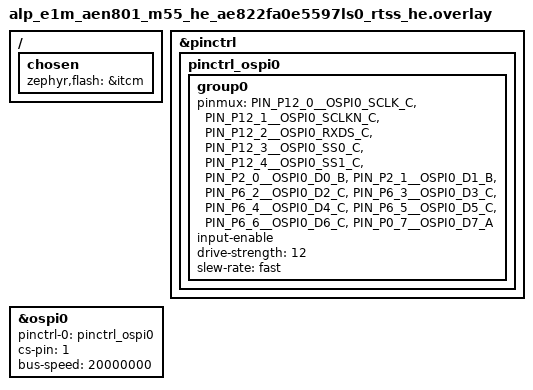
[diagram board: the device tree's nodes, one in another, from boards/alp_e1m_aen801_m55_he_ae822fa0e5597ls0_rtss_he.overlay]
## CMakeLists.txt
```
# SPDX-License-Identifier: Apache-2.0
#
# aen-ospi-regcheck -- compile + DT-bind proof of the Alif Ensemble OSPI/HexSPI
# controller (Synopsys DesignWare OSPI, zephyr/drivers/flash/flash_ospi_alif.c,
# compatible "snps,designware-ospi") staging on the E1M-AEN801 and E1M-AEN803
# (both Ensemble E8, M55-HE), via the bench RAM-run + RAM-console flow.
#
# Plain prj.conf app (no alp_project.py board.yaml emit). BUILD-ONLY: this
# proves the ospi0 node BINDS + alif_hal_ospi_initialize() compiles, links,
# and the register file reads back live -- not a live XiP read (XiP setup is
# a deliberate SKIP: OSPI_XIP_SER does not exist on AE822, independent of
# what's populated on the bus -- see src/main.c's CORRECTED PREMISE note,
# #2041) and not a device-level transfer of any kind (controller-register
# proof only). See src/main.c + the board overlay.

cmake_minimum_required(VERSION 3.20)

# No DTC_OVERLAY_FILE: Zephyr applies boards/<fully-qualified-board>.overlay by
# itself -- alp_e1m_aen801_m55_he_ae822fa0e5597ls0_rtss_he.overlay for
# `-b alp_e1m_aen801_m55_he/ae822fa0e5597ls0/rtss_he`, the aen803 file for the
# AEN803 target -- ITCM retarget included. Pinning the AEN801 file here, as
# this file used to, handed the AEN801 overlay to an AEN803 build and left the
# AEN803 one unread.

find_package(Zephyr REQUIRED HINTS $ENV{ZEPHYR_BASE})
project(aen_ospi_regcheck LANGUAGES C)

target_sources(app PRIVATE src/main.c)
```

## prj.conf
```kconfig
# SPDX-License-Identifier: Apache-2.0
#
# Bench RAM-run config for the E1M-AEN801 and E1M-AEN803 (M55-HE).

# Tier-1.5 driver Kconfigs (incl. CONFIG_OSPI_ALIF) are gated under ALP_SDK.
CONFIG_ALP_SDK=y

# This regcheck is specifically for the Ensemble E8 (E1M-AEN801 / E1M-AEN803).
CONFIG_ALP_SOC_ALIF_ENSEMBLE_E8=y

# The OSPI/HexSPI Tier-1.5 driver (zephyr/drivers/flash/flash_ospi_alif.c) --
# BUILD-ONLY: this app makes no device-level OSPI transfer (see src/main.c),
# only controller-register reads.  Pulls in USE_ALIF_HAL_OSPI (modules/hal/
# alif drivers/ospi).
CONFIG_OSPI_ALIF=y
CONFIG_FLASH=y

# CRC32 for the #915 program/erase self-test (src/main.c,
# AEN_OSPI_ENABLE_PROGRAM_ERASE_SELFTEST) -- off by default, but always
# compiled, so this Kconfig is always needed regardless of that flag.
CONFIG_CRC=y

# Console: Alp UART console -- E1M edge UART0 (Alif UART5, P3_4/P3_5, 115200
# 8N1, NS16550), the E1M-AEN carrier console. The board _defconfig already
# selects it; we set it explicitly here so the example is self-describing.
CONFIG_SERIAL=y
CONFIG_CONSOLE=y
CONFIG_UART_CONSOLE=y
CONFIG_UART_INTERRUPT_DRIVEN=y
# Serial-less bench? Comment the four lines above and uncomment these to read
# 'ram_console_buf' over SWD instead:
# CONFIG_RAM_CONSOLE=y
# CONFIG_RAM_CONSOLE_BUFFER_SIZE=2048
# CONFIG_UART_CONSOLE=n
CONFIG_PRINTK=y

# Keep the image small + deterministic for a RAM-run.
CONFIG_LOG=n
```

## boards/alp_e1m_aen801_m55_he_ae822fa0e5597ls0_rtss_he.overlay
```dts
/*
 * Copyright (c) 2026 Alp Lab AB
 * SPDX-License-Identifier: Apache-2.0
 *
 * aen-ospi-regcheck overlay for the E1M-AEN801 (Ensemble E8, M55-HE) RAM-run.
 *
 * Enables the Alif OSPI/HexSPI node so it BINDS on silicon:
 *   - ospi0 (snps,designware-ospi @ 0x83000000, IRQ 96, aes-reg 0x83001000,
 *     xip-base 0xA0000000/0x10000000)
 *
 * SCOPE: this proves the ospi0 node BINDS (DT_HAS_SNPS_DESIGNWARE_OSPI_ENABLED
 * + the reg/irq match) and that the flash_ospi_alif.c driver's
 * alif_hal_ospi_initialize() call compiles and links.  XiP setup itself is
 * skipped outright (OSPI_XIP_SER does not exist on AE822, independent of
 * what's on the bus -- see flash_ospi_alif.c and src/main.c).  This app
 * performs no device-level transfer, so nothing here confirms or denies a
 * part on either chip select; see src/main.c's header for the CORRECTED
 * PREMISE note (#2041) on what IS now known about SS1.
 *
 * CORRECTED (#2041): this overlay's pinctrl-0 previously muxed the Alif
 * DevKit's own OSPI0 route (zephyr_alif fork's ensemble-e4-e6-e8-pinctrl.dtsi
 * pinctrl_ospi0 "_B" group -- SCLK/RXDS/SS0 on port 3, D0-D7 on port 2), a
 * pad set that does not exist on the E1M-AEN module at all.  Because
 * flash_ospi_alif.c had no pinctrl support (see that file), pinctrl-0 was
 * also never applied, so this drove nothing regardless.  Both are fixed now:
 * the driver applies pinctrl-0 in its init, and the group below is
 * transcribed from metadata/e1m_modules/aen/alif-ospi.tsv, the E1M-AEN
 * module's actual OSPI0 routing (13 pads on ports 0/2/6/12, all function 1)
 * -- the same routing a silicon JEDEC-ID read used to confirm a populated
 * NOR at SS1 on E1M-AEN803 (see src/main.c).  Pad config
 * (input-enable/drive-strength=12/slew-rate=fast) is unchanged from the
 * prior group -- generic Alif pad electrical settings, not route-specific.
 *
 * cs-pin/bus-speed below match the paired AEN803 overlay (SS1/CS1, 20 MHz)
 * to preserve the same-PCB content invariant, even though this SKU fits no
 * OSPI memory and never transfers.
 */
#include <zephyr/dt-bindings/pinctrl/alif-ensemble-pinctrl.h>

/*
 * MANDATORY bench RAM-run retarget: run from ITCM so J-Link can loadbin+run
 * without programming MRAM, and drop the MCUboot code-partition fixup.
 */
/ {
	chosen {
		zephyr,flash = &itcm;
		/delete-property/ zephyr,code-partition;
	};
};

&pinctrl {
	pinctrl_ospi0: pinctrl_ospi0 {
		group0 {
			/* metadata/e1m_modules/aen/alif-ospi.tsv -- E1M-AEN module OSPI0
			 * routing, 13 pads, all function 1. */
			pinmux = <PIN_P12_0__OSPI0_SCLK_C>,
				 <PIN_P12_1__OSPI0_SCLKN_C>,
				 <PIN_P12_2__OSPI0_RXDS_C>,
				 <PIN_P12_3__OSPI0_SS0_C>,
				 <PIN_P12_4__OSPI0_SS1_C>,
				 <PIN_P2_0__OSPI0_D0_B>,
				 <PIN_P2_1__OSPI0_D1_B>,
				 <PIN_P6_2__OSPI0_D2_C>,
				 <PIN_P6_3__OSPI0_D3_C>,
				 <PIN_P6_4__OSPI0_D4_C>,
				 <PIN_P6_5__OSPI0_D5_C>,
				 <PIN_P6_6__OSPI0_D6_C>,
				 <PIN_P0_7__OSPI0_D7_A>;
			input-enable;
			drive-strength = <12>;
			slew-rate = "fast";
		};
	};
};

&ospi0 {
	status = "okay";
	pinctrl-0 = <&pinctrl_ospi0>;
	pinctrl-names = "default";
	cs-pin = <1>;
	bus-speed = <20000000>;
};
```

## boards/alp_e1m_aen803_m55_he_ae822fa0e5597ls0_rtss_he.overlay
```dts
/*
 * Copyright (c) 2026 Alp Lab AB
 * SPDX-License-Identifier: Apache-2.0
 *
 * aen-ospi-regcheck overlay for the E1M-AEN803 (Ensemble E8, M55-HE) RAM-run.
 *
 * Enables the Alif OSPI/HexSPI node so it BINDS on silicon:
 *   - ospi0 (snps,designware-ospi @ 0x83000000, IRQ 96, aes-reg 0x83001000,
 *     xip-base 0xA0000000/0x10000000)
 *
 * SCOPE: this proves the ospi0 node BINDS (DT_HAS_SNPS_DESIGNWARE_OSPI_ENABLED
 * + the reg/irq match) and that the flash_ospi_alif.c driver's
 * alif_hal_ospi_initialize() call compiles and links.  XiP setup itself is
 * skipped outright (OSPI_XIP_SER does not exist on AE822, independent of
 * what's on the bus -- see flash_ospi_alif.c and src/main.c).  This app
 * performs no device-level transfer, so nothing here confirms or denies a
 * part on either chip select; see src/main.c's header for the CORRECTED
 * PREMISE note (#2041) on what IS now known about SS1.
 *
 * CORRECTED (#2041): this overlay's pinctrl-0 previously muxed the Alif
 * DevKit's own OSPI0 route (zephyr_alif fork's ensemble-e4-e6-e8-pinctrl.dtsi
 * pinctrl_ospi0 "_B" group -- SCLK/RXDS/SS0 on port 3, D0-D7 on port 2), a
 * pad set that does not exist on the E1M-AEN module at all.  Because
 * flash_ospi_alif.c had no pinctrl support (see that file), pinctrl-0 was
 * also never applied, so this drove nothing regardless.  Both are fixed now:
 * the driver applies pinctrl-0 in its init, and the group below is
 * transcribed from metadata/e1m_modules/aen/alif-ospi.tsv, the E1M-AEN
 * module's actual OSPI0 routing (13 pads on ports 0/2/6/12, all function 1)
 * -- the same routing a silicon JEDEC-ID read used to confirm a populated
 * NOR at SS1 on E1M-AEN803 (see src/main.c).  Pad config
 * (input-enable/drive-strength=12/slew-rate=fast) is unchanged from the
 * prior group -- generic Alif pad electrical settings, not route-specific.
 *
 * cs-pin/bus-speed below override the dtsi defaults (cs-pin 0, 100 MHz):
 * SS1/CS1 is where the fitted IS25WX256-JHLE answers, not CS0 (that's the
 * HyperRAM footprint), and 20 MHz is the rate issue #915's own bench capture
 * used (100 MHz returned garbage, RISR error bit set). Without this override
 * any flash_driver_api call on this node targets the wrong chip select at an
 * unverified rate. The paired AEN801 overlay carries the same two values to
 * preserve the same-PCB content invariant, even though that SKU fits no
 * target and never transfers.
 */
#include <zephyr/dt-bindings/pinctrl/alif-ensemble-pinctrl.h>

/*
 * MANDATORY bench RAM-run retarget: run from ITCM so J-Link can loadbin+run
 * without programming MRAM, and drop the MCUboot code-partition fixup.
 */
/ {
	chosen {
		zephyr,flash = &itcm;
		/delete-property/ zephyr,code-partition;
	};
};

&pinctrl {
	pinctrl_ospi0: pinctrl_ospi0 {
		group0 {
			/* metadata/e1m_modules/aen/alif-ospi.tsv -- E1M-AEN module OSPI0
			 * routing, 13 pads, all function 1. */
			pinmux = <PIN_P12_0__OSPI0_SCLK_C>,
				 <PIN_P12_1__OSPI0_SCLKN_C>,
				 <PIN_P12_2__OSPI0_RXDS_C>,
				 <PIN_P12_3__OSPI0_SS0_C>,
				 <PIN_P12_4__OSPI0_SS1_C>,
				 <PIN_P2_0__OSPI0_D0_B>,
				 <PIN_P2_1__OSPI0_D1_B>,
				 <PIN_P6_2__OSPI0_D2_C>,
				 <PIN_P6_3__OSPI0_D3_C>,
				 <PIN_P6_4__OSPI0_D4_C>,
				 <PIN_P6_5__OSPI0_D5_C>,
				 <PIN_P6_6__OSPI0_D6_C>,
				 <PIN_P0_7__OSPI0_D7_A>;
			input-enable;
			drive-strength = <12>;
			slew-rate = "fast";
		};
	};
};

&ospi0 {
	status = "okay";
	pinctrl-0 = <&pinctrl_ospi0>;
	pinctrl-names = "default";
	cs-pin = <1>;
	bus-speed = <20000000>;
};
```

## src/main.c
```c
/*
 * Copyright (c) 2026 Alp Lab AB
 * SPDX-License-Identifier: Apache-2.0
 *
 * aen-ospi-regcheck -- compile + DT-bind + register-file proof of the Alif
 * Ensemble OSPI/HexSPI controller (Synopsys DesignWare OSPI, compatible
 * "snps,designware-ospi") on the E1M-AEN801 and E1M-AEN803 (Ensemble E8,
 * M55-HE), via the bench RAM-run + RAM-console flow.  Mirrors
 * aen-isp-regcheck.
 *
 * WHAT THIS APP VALIDATES (and what it deliberately does NOT):
 *
 *   The Alif Ensemble OSPI/HexSPI is an octal-SPI controller that also drives
 *   HyperBus/HyperRAM-style parts in XiP mode.  It is driven by the alp-sdk
 *   Tier-1.5 driver zephyr/drivers/flash/flash_ospi_alif.c, written over the
 *   Apache-2.0 hal_alif drivers/ospi register library (whose init entry
 *   point, alif_hal_ospi_initialize(), this app ALSO calls directly below, as
 *   an independent reachability proof: the hal_alif OSPI library statically
 *   holds only HAL_OSPI_MAX_INST=2 instance slots, and a call from the
 *   driver's own POST_KERNEL init plus this app's direct call both succeed
 *   against the same two-slot table).
 *
 *   So this app validates what IS deliverable build-green on this batch:
 *     1. the ospi0 node EXISTS and BINDS to its expected compatible
 *        ("snps,designware-ospi"),
 *     2. the reg base + aes-reg base + IRQ the node carries match the fork
 *        e1.dtsi (reg 0x83000000, aes-reg 0x83001000, IRQ 96),
 *     3. the flash_ospi_alif.c driver TU is built AND linked
 *        (CONFIG_OSPI_ALIF), the device INSTANTIATES, and
 *     4. alif_hal_ospi_initialize() -- the one hal_alif entry point the
 *        driver calls -- compiles, links, and is REACHABLE when called a
 *        second time directly from application code (LTO can't dead-strip a
 *        called symbol), AND
 *     5. the OSPI register file is genuinely LIVE and readable: CTRLR0 (the
 *        controller's power-on-reset register) reads back its documented
 *        reset value 0x00C00407 (SVD
 *        AE822FA0E5597BS0_CM55_HE_View.svd:75097, cross-checked in the
 *        driver's file-header MEASURED block) -- a real bus read, not merely
 *        "the call returned".
 *
 * WHY XiP IS SKIPPED, NOT ATTEMPTED: XiP setup (alif_hal_ospi_xip_enable())
 * is not called here at all.  OSPI_XIP_SER (offset 0x10C), the register that
 * call touches, DOES NOT EXIST on this die (SOC_FEAT_OSPI_HAS_XIP_SER=0,
 * AE822-specific -- see flash_ospi_alif.c's file-header FOURTH section for
 * the full citation chain) -- calling it bus-faults every time,
 * unconditionally, on every AE822 board regardless of what any OSPI chip
 * select carries.  There is no rc to catch: hal_alif's
 * alif_hal_ospi_xip_enable() (ospi_hal.c:397-416) returns OSPI_ERR_NONE
 * unconditionally after its register writes -- the ONLY failure mode is the
 * fault itself, so a prior version of this app that called it and "tolerated
 * a nonzero rc" was testing a premise that could never fail on its own terms
 * while the real failure (a crash before the RESULT line) went unreported.
 * This app instead states the SKIP explicitly: "no XiP slave in DT;
 * SOC_FEAT_OSPI_HAS_XIP_SER=0 on AE822".  This one die-level reason is
 * sufficient on its own and needs no premise about what's populated.
 *
 * CORRECTED PREMISE (#2041): a prior version of this header also justified
 * the skip with a second, board-population layer -- "the bench unit has NO
 * OSPI memory fitted (maintainer, 2026-08-30)", against a design-intent
 * Macronix MX25UM25645GXDI00 at SS1 per the module BOM.  That premise is now
 * known WRONG.  OSPI0 SS1 (CS1) on E1M-AEN803, serial 2026W36-0002, answers
 * a JEDEC ID read (opcode 0x9F, and again on the alternate ISSI opcode 0x9E)
 * with `9d 5b 19 10` -- 0x9d = ISSI, 5b 19 = the IS25WX256 type/capacity
 * pair -- i.e. a populated ISSI IS25WX256-JHLE, not a Macronix part, and not
 * empty.  See metadata/e1m_modules/E1M-AEN801.yaml (NOR now mapped to SS1 to
 * match) and metadata/e1m_modules/aen/alif-ospi.tsv, the shared AEN-family
 * OSPI0 pinout both that measurement and this app's pinctrl group (see the
 * board overlay) derive from.
 *
 * That measurement was NOT taken through this app.  In its DEFAULT mode
 * everything below is a controller-register proof (DT bind, reg/aes-reg/irq
 * match, CTRLR0 readback) with ZERO device-level transfers -- no opcode is
 * shifted out to a chip select -- so a default-mode PASS is not evidence
 * either way about whether a part answers on ITS specific board.  The
 * opt-in #915 self-test further down is the device-level check: it erases,
 * programs, reads back and restores one sector.
 *
 * BOTH SKUs, SAME APP (#2198): E1M-AEN803 fits the OSPI0 HyperRAM
 * (S80KS5122GABHM02, SS0) and the xSPI NOR (IS25WX256-JHLE, SS1) that
 * E1M-AEN801 leaves unpopulated.  On AEN803 those parts ARE on the bus and
 * this app still leaves them untouched: it only binds the node, checks
 * alif_hal_ospi_initialize()'s rc and reads CTRLR0 back against its reset
 * value 0x00C00407 -- no device transfer, no reset pulse on P15_6/P15_7, no
 * XIP, no write.  So its PASS/FAIL does not depend on what the chip selects
 * carry, and the AEN803 board overlay is the AEN801 one with the SKU changed.
 * It has already run on AEN803 silicon: #2041's 2026-09-13 bench check built
 * this app for the AEN801 target and ran it on E1M-AEN803 serial
 * 2026W36-0001 and E1M-AEN803 serial 2026W36-0002 -- rc=0, CTRLR0=0x00c00407, RESULT PASS on
 * both (docs/verification-status.md, OSPI0 pinctrl row).
 *
 * This example has caught three real, distinct silicon/build bugs (the
 * clock-gate fault, the MPU Device-mapping regression, and the OSPI_XIP_SER
 * fault above) purely at the controller-register level -- it is a
 * regression sentinel, not a formality.  The clock-gate, MPU, and
 * register-file checks below MUST still surface as loud
 * device_is_ready()/init/readback failures if any of those three regress;
 * only the XiP step is a deliberate, explained skip.
 */

#include <stdbool.h>
#include <stdint.h>
#include <string.h>

#include <cmsis_core.h>
#include <zephyr/device.h>
#include <zephyr/devicetree.h>
#include <zephyr/drivers/flash.h>
#include <zephyr/fatal.h>
#include <zephyr/kernel.h>
#include <zephyr/sys/crc.h>
#include <zephyr/sys/printk.h>

#include <ospi_hal.h>

/* The OSPI node (status set by the board overlay). */
#define OSPI_NODE DT_NODELABEL(ospi0)

/*
 * A hal_alif call in this app can bus-fault before reaching the RESULT
 * PASS/FAIL gate at the bottom of main() (see the flash_ospi_alif.c file
 * header for the fault history this driver's init used to be able to hit) --
 * that would otherwise produce NO "RESULT" line at all, a bench NO-RESULT
 * that hides a real failure behind a state the harness can't tell apart from
 * "still running". Overriding the weak default (kernel/fatal.c) makes the
 * crash path self-reporting: print a RESULT FAIL naming the fatal reason
 * code to the RAM console, then hand off to the normal halt so nothing else
 * runs. The prefix is deliberately the same "RESULT FAIL:" the bottom-of-main
 * gate uses (so a simple grep for RESULT catches this path too) but the text
 * after it can never be mistaken for the success line -- that line is
 * "RESULT PASS: ..." and is only ever reached by returning normally past
 * this handler, which never returns.
 */
void k_sys_fatal_error_handler(unsigned int reason, const struct arch_esf *esf)
{
	ARG_UNUSED(esf);
	printk("RESULT FAIL: fatal error before the PASS/FAIL gate could run (reason=%u) -- "
	       "a hal_alif call trapped (see flash_ospi_alif.c's file-header fault history)\n",
	       reason);
	for (;;) {
		__WFE();
	}
}

/*
 * Expected reg/aes-reg base + IRQ.  Transcribed VERBATIM from the fork's
 * e1.dtsi ospi0 node (reg 0x83000000/0x1000, aes-reg 0x83001000/0x100, IRQ
 * 96) -- see the OSPI_ALIF Kconfig + the SoC dtsi node comment for the
 * full provenance.  Read the LIVE values from devicetree and compare, so
 * this stays correct if the node ever moves and catches a binding that
 * resolved to the wrong node.
 */
#define OSPI_BASE_EXPECTED     0x83000000U
#define OSPI_AES_BASE_EXPECTED 0x83001000U
#define OSPI_IRQ_EXPECTED      96U

/*
 * OSPI_CTRLR0's documented power-on-reset value (struct ospi_regs, ospi.h,
 * offset 0x00) -- cross-checked against the SVD's CTRLR0 resetValue in the
 * driver's file-header MEASURED block
 * (AE822FA0E5597BS0_CM55_HE_View.svd:75097).  A readback matching this proves
 * the register FILE is genuinely live on the bus (clock gate open, MPU
 * region mapped Device, controller actually answering), not merely that a
 * hal_alif call returned a success code.
 */
#define OSPI_CTRLR0_RESET_VALUE 0x00C00407U

/*
 * Compile-time staging fact: 1 iff the ospi0 node exists, is enabled, and
 * binds to its expected compatible.  A pure DT predicate -- independent of
 * device_is_ready / whether the driver TU was built.
 */
#define OSPI_BOUND \
	(DT_NODE_HAS_STATUS(OSPI_NODE, okay) && DT_NODE_HAS_COMPAT(OSPI_NODE, snps_designware_ospi))

/*
 * #915 program/erase self-test -- OFF by default. This performs a real
 * destructive erase + program on ONE sector of whatever OSPI0 CS1 part is
 * fitted, so it must never run by accident: flip
 * AEN_OSPI_ENABLE_PROGRAM_ERASE_SELFTEST to 1 (a deliberate source edit, not
 * a Kconfig a stale build cache could carry over) before flashing this app
 * if you intend to run it. Always compiled and typechecked either way, so
 * it cannot silently bit-rot while switched off.
 *
 * SECTOR CHOICE: 0x01FF0000, one 4 KiB sector near the top of the 32 MiB
 * (256 Mbit) IS25WX256 array (FLASH_ISSI_SECTOR_SIZE, alif-dfp-ref
 * components/Include/IS25WX256.h) -- picked to sit well clear of any low
 * address a bootloader or XiP image might ever occupy, and named as a
 * literal constant rather than derived from a part size this driver does
 * not know at compile time (see flash_ospi_alif.c's read() ponytail note).
 * The loop below touches ONLY this one address range: it reads it back
 * before touching anything, restores exactly what it read, and never
 * computes a second address anywhere.
 */
#define AEN_OSPI_ENABLE_PROGRAM_ERASE_SELFTEST 0
#define AEN_OSPI_SELFTEST_OFFSET               0x01FF0000U
#define AEN_OSPI_SELFTEST_SECTOR_SIZE          4096U

static uint8_t aen_ospi_selftest_original[AEN_OSPI_SELFTEST_SECTOR_SIZE];
static uint8_t aen_ospi_selftest_scratch[AEN_OSPI_SELFTEST_SECTOR_SIZE];

/*
 * Erase + program + restore ONE sector, proving flash_write()/flash_erase()
 * against a known pattern and leaving the part exactly as found. Never
 * touches any address outside [AEN_OSPI_SELFTEST_OFFSET,
 * AEN_OSPI_SELFTEST_OFFSET + AEN_OSPI_SELFTEST_SECTOR_SIZE).
 */
static void aen_ospi_program_erase_selftest(const struct device *ospi_dev)
{
	uint32_t original_crc, blank_crc, pattern_crc, readback_crc, restored_crc;
	int      rc;
	bool     erase_ok   = false;
	bool     program_ok = false;

	printk("\n=== #915 program/erase self-test: sector 0x%08x ===\n", AEN_OSPI_SELFTEST_OFFSET);

	/* 1. Save what's there now -- this is what gets restored at the end. */
	rc = flash_read(ospi_dev,
	                AEN_OSPI_SELFTEST_OFFSET,
	                aen_ospi_selftest_original,
	                sizeof(aen_ospi_selftest_original));
	if (rc != 0) {
		printk("RESULT FAIL: initial flash_read() rc=%d\n", rc);
		return;
	}
	original_crc = crc32_ieee(aen_ospi_selftest_original, sizeof(aen_ospi_selftest_original));
	printk("original: crc32=0x%08x\n", original_crc);

	/* 2. Erase, then verify the sector actually reads back all-0xFF. */
	rc = flash_erase(ospi_dev, AEN_OSPI_SELFTEST_OFFSET, AEN_OSPI_SELFTEST_SECTOR_SIZE);
	if (rc != 0) {
		/* A failed erase may still have wiped part of the sector: restore. */
		printk("RESULT FAIL: flash_erase() rc=%d\n", rc);
		goto restore;
	}
	rc = flash_read(ospi_dev,
	                AEN_OSPI_SELFTEST_OFFSET,
	                aen_ospi_selftest_scratch,
	                sizeof(aen_ospi_selftest_scratch));
	if (rc != 0) {
		printk("RESULT FAIL: post-erase flash_read() rc=%d\n", rc);
		goto restore;
	}
	blank_crc = crc32_ieee(aen_ospi_selftest_scratch, sizeof(aen_ospi_selftest_scratch));
	erase_ok  = true;

	for (size_t i = 0; i < sizeof(aen_ospi_selftest_scratch); i++) {
		if (aen_ospi_selftest_scratch[i] != 0xFFU) {
			erase_ok = false;
			break;
		}
	}
	printk("post-erase: crc32=0x%08x all_0xff=%d\n", blank_crc, (int)erase_ok);

	/* 3. Program a known pattern, then read it back and compare. */
	for (size_t i = 0; i < sizeof(aen_ospi_selftest_scratch); i++) {
		aen_ospi_selftest_scratch[i] = (uint8_t)(i & 0xFFU);
	}
	pattern_crc = crc32_ieee(aen_ospi_selftest_scratch, sizeof(aen_ospi_selftest_scratch));
	rc          = flash_write(ospi_dev,
	                          AEN_OSPI_SELFTEST_OFFSET,
	                          aen_ospi_selftest_scratch,
	                          sizeof(aen_ospi_selftest_scratch));
	if (rc != 0) {
		printk("RESULT FAIL: flash_write() (pattern) rc=%d\n", rc);
		goto restore;
	}
	rc = flash_read(ospi_dev,
	                AEN_OSPI_SELFTEST_OFFSET,
	                aen_ospi_selftest_scratch,
	                sizeof(aen_ospi_selftest_scratch));
	if (rc != 0) {
		printk("RESULT FAIL: post-program flash_read() rc=%d\n", rc);
		goto restore;
	}
	readback_crc = crc32_ieee(aen_ospi_selftest_scratch, sizeof(aen_ospi_selftest_scratch));
	program_ok   = (readback_crc == pattern_crc);

	printk("pattern: crc32=0x%08x readback_crc32=0x%08x match=%d\n",
	       pattern_crc,
	       readback_crc,
	       (int)program_ok);

restore:
	/* 4. Restore the original contents unconditionally -- on a program
	 * mismatch AND on every early failure after the erase above (each of
	 * those jumps here) -- this sector must not be left erased or in the
	 * pattern state, whatever else this test concludes. */
	rc = flash_erase(ospi_dev, AEN_OSPI_SELFTEST_OFFSET, AEN_OSPI_SELFTEST_SECTOR_SIZE);
	if (rc == 0) {
		rc = flash_write(ospi_dev,
		                 AEN_OSPI_SELFTEST_OFFSET,
		                 aen_ospi_selftest_original,
		                 sizeof(aen_ospi_selftest_original));
	}
	if (rc != 0) {
		printk("RESULT FAIL: restore rc=%d -- sector 0x%08x may be left in the pattern "
		       "state, NOT its original contents\n",
		       rc,
		       AEN_OSPI_SELFTEST_OFFSET);
		return;
	}
	rc = flash_read(ospi_dev,
	                AEN_OSPI_SELFTEST_OFFSET,
	                aen_ospi_selftest_scratch,
	                sizeof(aen_ospi_selftest_scratch));
	if (rc != 0) {
		printk("RESULT FAIL: post-restore flash_read() rc=%d\n", rc);
		return;
	}
	restored_crc    = crc32_ieee(aen_ospi_selftest_scratch, sizeof(aen_ospi_selftest_scratch));
	bool restore_ok = (restored_crc == original_crc);

	printk("restored: crc32=0x%08x match=%d\n", restored_crc, (int)restore_ok);

	if (erase_ok && program_ok && restore_ok) {
		printk("RESULT PASS: #915 program/erase self-test -- sector 0x%08x erased "
		       "(all 0xFF), programmed pattern verified byte-for-byte, original "
		       "contents restored and CRC-verified\n",
		       AEN_OSPI_SELFTEST_OFFSET);
	} else {
		printk("RESULT FAIL: #915 program/erase self-test (erase_ok=%d program_ok=%d "
		       "restore_ok=%d)\n",
		       (int)erase_ok,
		       (int)program_ok,
		       (int)restore_ok);
	}
}

int main(void)
{
	printk("\n=== aen-ospi-regcheck ===\n");

	/*
	 * Step 1+2: report the node's binding + reg/aes-reg base + IRQ.
	 * DT_REG_ADDR / DT_PROP_BY_IDX / DT_IRQ_BY_IDX are build-time constants
	 * pulled from the bound node; a mismatch vs the fork e1.dtsi means the
	 * binding resolved to the wrong node.
	 */
	uint32_t ospi_base     = (uint32_t)DT_REG_ADDR(OSPI_NODE);
	uint32_t ospi_aes_base = (uint32_t)DT_PROP_BY_IDX(OSPI_NODE, aes_reg, 0);
	uint32_t ospi_irq      = (uint32_t)DT_IRQ_BY_IDX(OSPI_NODE, 0, irq);

	printk("ospi0 : %s\n", DT_NODE_FULL_NAME(OSPI_NODE));
	printk("        bound=%d compat=snps,designware-ospi base=0x%08x (exp 0x%08x) "
	       "aes_base=0x%08x (exp 0x%08x)\n",
	       (int)OSPI_BOUND,
	       ospi_base,
	       OSPI_BASE_EXPECTED,
	       ospi_aes_base,
	       OSPI_AES_BASE_EXPECTED);
	printk("        irq=%u (exp %u)\n", ospi_irq, OSPI_IRQ_EXPECTED);

	bool node_ok = OSPI_BOUND && (ospi_base == OSPI_BASE_EXPECTED) &&
	               (ospi_aes_base == OSPI_AES_BASE_EXPECTED) && (ospi_irq == OSPI_IRQ_EXPECTED);

	/*
	 * Step 3: the flash_ospi_alif.c driver TU is always built under this
	 * app's prj.conf (CONFIG_OSPI_ALIF=y), so DEVICE_DT_GET is safe here --
	 * unlike aen-isp-regcheck, there is no link-blocked driver TU on this
	 * batch. ospi_alif_init() writes the OSPI0 clock-enable (CLKCTL_PER_SLV
	 * ->OSPI_CTRL bit 0) before calling alif_hal_ospi_initialize(), and the
	 * OSPI register window is mapped MPU Device -- both fixes for real,
	 * previously-reproduced bus faults, see flash_ospi_alif.c's file
	 * header. device_is_ready() reading false here is a genuine RESULT FAIL
	 * of this app's own contract: it means one of those fixes has
	 * regressed, not that the missing external part is at fault (the
	 * missing part only ever excused the removed XiP-enable step, never
	 * anything upstream of it).
	 */
	const struct device *ospi_dev  = DEVICE_DT_GET(OSPI_NODE);
	bool                 dev_ready = device_is_ready(ospi_dev);

	if (!dev_ready) {
		printk("driver: flash_ospi_alif.c linked but device NOT ready (init failed)\n");
	} else {
		printk("driver: flash_ospi_alif.c linked, device READY (ospi_alif_init() "
		       "completed: alif_hal_ospi_initialize() ran at POST_KERNEL)\n");
	}

	/*
	 * Step 4: call alif_hal_ospi_initialize() a SECOND time, directly from
	 * application code, against DT-derived values -- an independent
	 * compile+link+reachability proof (LTO can't dead-strip a called
	 * symbol). The hal_alif OSPI library holds HAL_OSPI_MAX_INST=2 instance
	 * slots (modules/hal/alif drivers/ospi/src/ospi_hal.c); the driver's own
	 * POST_KERNEL init already took slot 0, so this call takes slot 1 --
	 * both succeed against the fixed two-slot table.
	 */
	/*
	 * core_clk: DT_PROP(OSPI_NODE, clock_frequency), NOT a `bus-speed`
	 * fallback -- see flash_ospi_alif.c:30-80. A fallback here wrote
	 * OSPI_BAUDR = core_clk / bus_speed = 1, and HWRM AHRM0012NDA v0.3
	 * S16.1.5.3.5 defines OSPI_BAUDR[SCKDV] = 0 as "OSPI_SCLK is
	 * disabled" -- a dead bus, not an overclock. The node always sets
	 * `clock-frequency` now, so this app mirrors the driver's plain
	 * DT_PROP() instead of quietly re-growing the same fallback one file
	 * over from the fix.
	 */
	HAL_OSPI_Handle_T app_handle = -1;
	struct ospi_init  app_cfg    = {
		.bus_speed       = DT_PROP(OSPI_NODE, bus_speed),
		.core_clk        = DT_PROP(OSPI_NODE, clock_frequency),
		.cs_pin          = DT_PROP(OSPI_NODE, cs_pin),
		.rx_ds_delay     = DT_PROP(OSPI_NODE, rx_ds_delay),
		.ddr_drive_edge  = DT_PROP(OSPI_NODE, ddr_drive_edge),
		.baud2_delay     = OSPI_BAUD2_DELAY_AUTO,
		.base_regs       = (uint32_t *)ospi_base,
		.aes_regs        = (uint32_t *)ospi_aes_base,
		.xip_wait_cycles = DT_PROP(OSPI_NODE, xip_wait_cycles),
	};

	int32_t init_rc = alif_hal_ospi_initialize(&app_handle, &app_cfg);

	printk("hal   : alif_hal_ospi_initialize() rc=%d handle=%d\n", init_rc, (int)app_handle);

	bool hal_init_ok = (init_rc == OSPI_ERR_NONE);

	/*
	 * Step 5: register-file readback. CTRLR0 sits at offset 0x00 of the OSPI
	 * register window -- read it straight off ospi_base (the same address
	 * both alif_hal_ospi_initialize() calls above were given) rather than
	 * through a hal_alif accessor, so this is an independent proof that the
	 * bus itself answers, not a restatement of "the call returned
	 * OSPI_ERR_NONE". By this point in main() the driver's POST_KERNEL init
	 * has already opened the clock gate and the MPU region is mapped
	 * Device, so this is a plain, safe 32-bit load -- if either of those
	 * regresses, this read faults and k_sys_fatal_error_handler() reports it
	 * instead of a silent hang.
	 */
	uint32_t ctrlr0    = *(volatile uint32_t *)ospi_base;
	bool     ctrlr0_ok = (ctrlr0 == OSPI_CTRLR0_RESET_VALUE);

	printk("hal   : CTRLR0=0x%08x (exp reset value 0x%08x)\n", ctrlr0, OSPI_CTRLR0_RESET_VALUE);

	/*
	 * Step 6: XiP is an explicit, stated SKIP -- not attempted. See the
	 * module header for why: OSPI_XIP_SER (offset 0x10C) does not exist on
	 * AE822 (SOC_FEAT_OSPI_HAS_XIP_SER=0), so alif_hal_ospi_xip_enable()
	 * bus-faults unconditionally; there is no rc that could report this as a
	 * recoverable failure (ospi_hal.c:397-416 returns OSPI_ERR_NONE
	 * unconditionally after the writes that fault).
	 */
	printk("hal   : alif_hal_ospi_xip_enable() SKIPPED -- no XiP slave in DT; "
	       "SOC_FEAT_OSPI_HAS_XIP_SER=0 on AE822 (register does not exist on this die)\n");

	/*
	 * PASS gate: the ospi0 node BINDS -- ospi0@83000000 binds to
	 * "snps,designware-ospi" at the fork reg/aes-reg base with IRQ 96 --
	 * AND the driver's own init left the device READY (dev_ready) -- AND
	 * alif_hal_ospi_initialize() was called and returned OSPI_ERR_NONE
	 * both from the driver's own init and directly from this app -- AND the
	 * register file reads back its documented CTRLR0 reset value. XiP setup
	 * is out of scope for this gate (see the module header SKIP note --
	 * OSPI_XIP_SER does not exist on AE822, independent of what any chip
	 * select carries); this app makes no device-level transfer either way,
	 * so its PASS says nothing about whether a NOR/HyperBus part answers.
	 */
	if (node_ok && dev_ready && hal_init_ok && ctrlr0_ok) {
		printk("RESULT PASS: OSPI/HexSPI node BINDS -- ospi0@83000000 binds to "
		       "snps,designware-ospi at the fork reg/aes-reg base with IRQ 96; "
		       "alif_hal_ospi_initialize() is reachable and links; CTRLR0 reads "
		       "its documented reset value; XiP SKIPPED (no XIP_SER on this die); "
		       "no device-level transfer attempted (controller-register proof only)\n");
	} else {
		printk("RESULT FAIL: OSPI/HexSPI node NOT staged "
		       "(bound=%d base_ok=%d irq_ok=%d dev_ready=%d hal_init_ok=%d ctrlr0_ok=%d -- node "
		       "missing, disabled, bound to the wrong compatible/reg/irq, the driver init "
		       "left the device not ready, the "
		       "hal_alif init call did not return OSPI_ERR_NONE, or the register "
		       "file did not read back its reset value)\n",
		       (int)OSPI_BOUND,
		       (int)(ospi_base == OSPI_BASE_EXPECTED && ospi_aes_base == OSPI_AES_BASE_EXPECTED),
		       (int)(ospi_irq == OSPI_IRQ_EXPECTED),
		       (int)dev_ready,
		       (int)hal_init_ok,
		       (int)ctrlr0_ok);
	}

	/*
	 * #915 program/erase self-test -- OFF unless AEN_OSPI_ENABLE_PROGRAM_
	 * ERASE_SELFTEST is flipped to 1 above. Requires device_is_ready() to
	 * have already succeeded (checked here, not just above) -- an erase/
	 * program attempt against a not-ready device is exactly the kind of
	 * silent-wrong-address risk this app's node-bind gate exists to catch.
	 */
	if (AEN_OSPI_ENABLE_PROGRAM_ERASE_SELFTEST) {
		if (device_is_ready(ospi_dev)) {
			aen_ospi_program_erase_selftest(ospi_dev);
		} else {
			printk("RESULT FAIL: #915 program/erase self-test SKIPPED -- ospi_dev "
			       "not ready\n");
		}
	}

	return 0;
}
```
